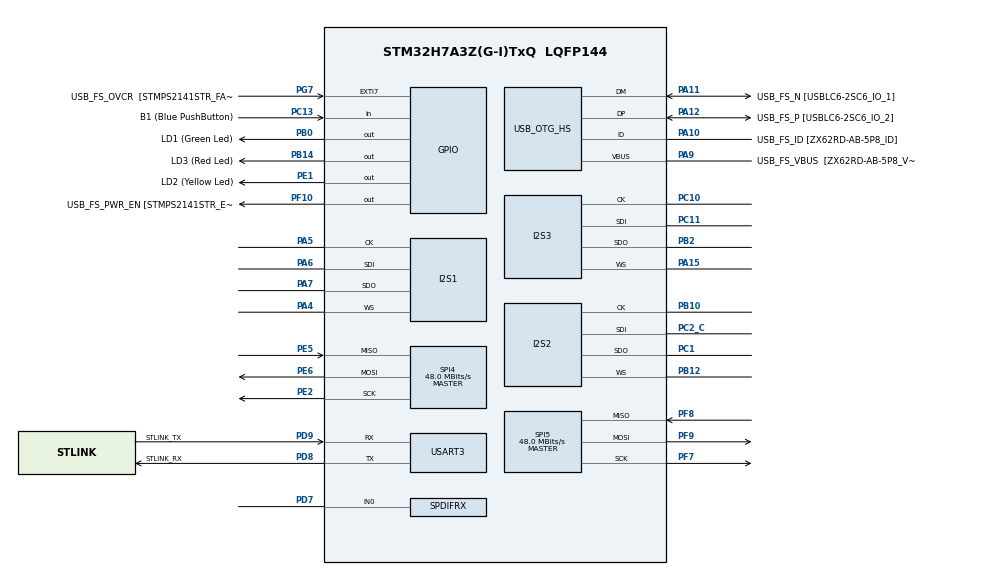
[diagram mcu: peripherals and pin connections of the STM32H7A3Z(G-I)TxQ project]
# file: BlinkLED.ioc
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I2S1.AudioFreq=I2S_AUDIOFREQ_48K
I2S1.ErrorAudioFreq=-0.79 %
I2S1.Instance=SPI$Index
I2S1.RealAudioFreq=47.619 KHz
I2S2.ErrorAudioFreq=0.0 %
I2S2.Instance=SPI$Index
I2S2.RealAudioFreq=8.0 KHz
I2S3.ErrorAudioFreq=0.0 %
I2S3.Instance=SPI$Index
I2S3.RealAudioFreq=8.0 KHz
Mcu.Family=STM32H7
Mcu.Name=STM32H7A3Z(G-I)TxQ
Mcu.Package=LQFP144
NVIC.PriorityGroup=NVIC_PRIORITYGROUP_4
PA10.GPIO_Label=USB_FS_ID [ZX62RD-AB-5P8_ID]
PA10.Mode=OTG/Dual-Role-Device-FS
PA10.Signal=USB_OTG_HS_ID
PA11.GPIO_Label=USB_FS_N [USBLC6-2SC6_IO_1]
PA11.Mode=OTG/Dual-Role-Device-FS
PA11.Signal=USB_OTG_HS_DM
PA12.GPIO_Label=USB_FS_P [USBLC6-2SC6_IO_2]
PA12.Mode=OTG/Dual-Role-Device-FS
PA12.Signal=USB_OTG_HS_DP
PA15.Mode=Full_Duplex_Master
PA15.Signal=I2S3_WS
PA4.Mode=Full_Duplex_Master
PA4.Signal=I2S1_WS
PA5.Mode=Full_Duplex_Master
PA5.Signal=I2S1_CK
PA6.Mode=Full_Duplex_Master
PA6.Signal=I2S1_SDI
PA7.Mode=Full_Duplex_Master
PA7.Signal=I2S1_SDO
PA9.GPIO_Label=USB_FS_VBUS  [ZX62RD-AB-5P8_VBUS]
PA9.Mode=Activate_VBUS_FS
PA9.Signal=USB_OTG_HS_VBUS
PB0.GPIO_Label=LD1 (Green Led)
PB0.Signal=GPIO_Output
PB10.Mode=Full_Duplex_Master
PB10.Signal=I2S2_CK
PB12.Mode=Full_Duplex_Master
PB12.Signal=I2S2_WS
PB14.GPIO_Label=LD3 (Red Led)
PB14.Signal=GPIO_Output
PB2.Mode=Full_Duplex_Master
PB2.Signal=I2S3_SDO
PC1.Mode=Full_Duplex_Master
PC1.Signal=I2S2_SDO
PC10.Mode=Full_Duplex_Master
PC10.Signal=I2S3_CK
PC11.Mode=Full_Duplex_Master
PC11.Signal=I2S3_SDI
PC13.GPIO_Label=B1 (Blue PushButton)
PC13.Signal=GPIO_Input
PC14-OSC32_IN.GPIO_Label=OSC32_IN
PC14-OSC32_IN.Mode=LSE-External-Oscillator
PC14-OSC32_IN.Signal=RCC_OSC32_IN
PC15-OSC32_OUT.GPIO_Label=OSC32_OUT
PC15-OSC32_OUT.Mode=LSE-External-Oscillator
PC15-OSC32_OUT.Signal=RCC_OSC32_OUT
PC2_C.Mode=Full_Duplex_Master
PC2_C.Signal=I2S2_SDI
PD7.Mode=IN0
PD7.Signal=SPDIFRX_IN0
PD8.GPIO_Label=STLINK_RX
PD8.Mode=Asynchronous
PD8.Signal=USART3_TX
PD9.GPIO_Label=STLINK_TX
PD9.Mode=Asynchronous
PD9.Signal=USART3_RX
PE1.GPIO_Label=LD2 (Yellow Led)
PE1.Signal=GPIO_Output
PE2.Mode=Full_Duplex_Master
PE2.Signal=SPI4_SCK
PE5.Mode=Full_Duplex_Master
PE5.Signal=SPI4_MISO
PE6.Mode=Full_Duplex_Master
PE6.Signal=SPI4_MOSI
PF10.GPIO_Label=USB_FS_PWR_EN [STMPS2141STR_EN]
PF10.Signal=GPIO_Output
PF7.Mode=Full_Duplex_Master
PF7.Signal=SPI5_SCK
PF8.Mode=Full_Duplex_Master
PF8.Signal=SPI5_MISO
PF9.Mode=Full_Duplex_Master
PF9.Signal=SPI5_MOSI
PG7.GPIO_Label=USB_FS_OVCR  [STMPS2141STR_FAULT]
PG7.Signal=GPXTI7
PH0-OSC_IN.GPIO_Label=PH0-MCU
PH0-OSC_IN.Mode=HSE-External-Clock-Source
PH0-OSC_IN.Signal=RCC_OSC_IN
PH1-OSC_OUT.GPIO_Label=PH1-MCU
PH1-OSC_OUT.Signal=RCC_OSC_OUT
ProjectManager.HeapSize=0x200
ProjectManager.StackSize=0x400
ProjectManager.TargetToolchain=MDK-ARM V5.32
RCC.ADCFreq_Value=32000000
RCC.APB1Freq_Value=96000000
RCC.APB2Freq_Value=96000000
RCC.APB3Freq_Value=96000000
RCC.APB4Freq_Value=96000000
RCC.CortexFreq_Value=96000000
RCC.DIVM1=1
RCC.DIVM2=1
RCC.DIVM3=1
RCC.DIVN1=24
RCC.DIVN2=16
RCC.DIVN3=24
RCC.DIVP2=4
RCC.DIVQ1=4
RCC.HCLKFreq_Value=96000000
RCC.HSE_VALUE=8000000
RCC.PLL3FRACN=0
RCC.PLLFRACN=0
RCC.PLLSourceVirtual=RCC_PLLSOURCE_HSE
RCC.PWR_Regulator_Voltage_Scale=PWR_REGULATOR_VOLTAGE_SCALE0
RCC.SPI123CLockSelection=RCC_SPI123CLKSOURCE_PLL3
RCC.SYSCLKFreq_VALUE=96000000
RCC.SYSCLKSource=RCC_SYSCLKSOURCE_PLLCLK
RCC.SupplySource=PWR_DIRECT_SMPS_SUPPLY
RCC.USBCLockSelection=RCC_USBCLKSOURCE_HSI48
RCC.USBFreq_Value=48000000
SPI4.CalculateBaudRate=48.0 MBits/s
SPI4.Direction=SPI_DIRECTION_2LINES
SPI4.Mode=SPI_MODE_MASTER
SPI4.VirtualType=VM_MASTER
SPI5.CalculateBaudRate=48.0 MBits/s
SPI5.Direction=SPI_DIRECTION_2LINES
SPI5.Mode=SPI_MODE_MASTER
SPI5.VirtualType=VM_MASTER
USART3.VirtualMode-Asynchronous=VM_ASYNC
VP_MEMORYMAP_VS_MEMORYMAP.Mode=CurAppReg
board=NUCLEO-H7A3ZI-Q

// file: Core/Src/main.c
/* USER CODE BEGIN Header */
/**
  ******************************************************************************
  * @file           : main.c
  * @brief          : Main program body
  ******************************************************************************
  * @attention
  *
  * Copyright (c) 2024 STMicroelectronics.
  * All rights reserved.
  *
  * This software is licensed under terms that can be found in the LICENSE file
  * in the root directory of this software component.
  * If no LICENSE file comes with this software, it is provided AS-IS.
  *
  ******************************************************************************
  */
/* USER CODE END Header */
#include "main.h"
#include "i2s.h"
#include "memorymap.h"
#include "spdifrx.h"
#include "spi.h"
#include "usart.h"
#include "usb_otg.h"
#include "gpio.h"

void SystemClock_Config(void);
void PeriphCommonClock_Config(void);

int main(void)
{

  /* MCU Configuration--------------------------------------------------------*/

  /* Reset of all peripherals, Initializes the Flash interface and the Systick. */
  HAL_Init();

  /* Configure the system clock */
  SystemClock_Config();

  /* Configure the peripherals common clocks */
  PeriphCommonClock_Config();

  /* Initialize all configured peripherals */
  MX_GPIO_Init();
  MX_I2S1_Init();
  MX_I2S2_Init();
  MX_I2S3_Init();
  MX_SPDIFRX_Init();
  MX_SPI4_Init();
  MX_SPI5_Init();
  MX_USART3_UART_Init();
  MX_USB_OTG_HS_USB_Init();

  /* Infinite loop */
  /* USER CODE BEGIN WHILE */
  while (1)
  {
		//while((GPIOC->IDR & GPIO_PIN_13));
		//while(!(GPIOC->IDR & GPIO_PIN_13));

    /* USER CODE END WHILE */
		HAL_GPIO_TogglePin(GPIOB, GPIO_PIN_14);
		HAL_Delay(1);
  }
}

void SystemClock_Config(void)
{
  RCC_OscInitTypeDef RCC_OscInitStruct = {0};
  RCC_ClkInitTypeDef RCC_ClkInitStruct = {0};

  /*AXI clock gating */
  RCC->CKGAENR = 0xFFFFFFFF;

  /** Supply configuration update enable
  */
  HAL_PWREx_ConfigSupply(PWR_DIRECT_SMPS_SUPPLY);

  /** Configure the main internal regulator output voltage
  */
  __HAL_PWR_VOLTAGESCALING_CONFIG(PWR_REGULATOR_VOLTAGE_SCALE0);

  while(!__HAL_PWR_GET_FLAG(PWR_FLAG_VOSRDY)) {}

  /** Initializes the RCC Oscillators according to the specified parameters
  * in the RCC_OscInitTypeDef structure.
  */
  RCC_OscInitStruct.OscillatorType = RCC_OSCILLATORTYPE_HSI48|RCC_OSCILLATORTYPE_HSE;
  RCC_OscInitStruct.HSEState = RCC_HSE_BYPASS;
  RCC_OscInitStruct.HSI48State = RCC_HSI48_ON;
  RCC_OscInitStruct.PLL.PLLState = RCC_PLL_ON;
  RCC_OscInitStruct.PLL.PLLSource = RCC_PLLSOURCE_HSE;
  RCC_OscInitStruct.PLL.PLLM = 1;
  RCC_OscInitStruct.PLL.PLLN = 24;
  RCC_OscInitStruct.PLL.PLLP = 2;
  RCC_OscInitStruct.PLL.PLLQ = 4;
  RCC_OscInitStruct.PLL.PLLR = 2;
  RCC_OscInitStruct.PLL.PLLRGE = RCC_PLL1VCIRANGE_3;
  RCC_OscInitStruct.PLL.PLLVCOSEL = RCC_PLL1VCOWIDE;
  RCC_OscInitStruct.PLL.PLLFRACN = 0;
  if (HAL_RCC_OscConfig(&RCC_OscInitStruct) != HAL_OK)
  {
    Error_Handler();
  }

  /** Initializes the CPU, AHB and APB buses clocks
  */
  RCC_ClkInitStruct.ClockType = RCC_CLOCKTYPE_HCLK|RCC_CLOCKTYPE_SYSCLK
                              |RCC_CLOCKTYPE_PCLK1|RCC_CLOCKTYPE_PCLK2
                              |RCC_CLOCKTYPE_D3PCLK1|RCC_CLOCKTYPE_D1PCLK1;
  RCC_ClkInitStruct.SYSCLKSource = RCC_SYSCLKSOURCE_PLLCLK;
  RCC_ClkInitStruct.SYSCLKDivider = RCC_SYSCLK_DIV1;
  RCC_ClkInitStruct.AHBCLKDivider = RCC_HCLK_DIV1;
  RCC_ClkInitStruct.APB3CLKDivider = RCC_APB3_DIV1;
  RCC_ClkInitStruct.APB1CLKDivider = RCC_APB1_DIV1;
  RCC_ClkInitStruct.APB2CLKDivider = RCC_APB2_DIV1;
  RCC_ClkInitStruct.APB4CLKDivider = RCC_APB4_DIV1;

  if (HAL_RCC_ClockConfig(&RCC_ClkInitStruct, FLASH_LATENCY_2) != HAL_OK)
  {
    Error_Handler();
  }
}

void PeriphCommonClock_Config(void)
{
  RCC_PeriphCLKInitTypeDef PeriphClkInitStruct = {0};

  /** Initializes the peripherals clock
  */
  PeriphClkInitStruct.PeriphClockSelection = RCC_PERIPHCLK_SPI3|RCC_PERIPHCLK_SPI2
                              |RCC_PERIPHCLK_SPI1;
  PeriphClkInitStruct.PLL3.PLL3M = 1;
  PeriphClkInitStruct.PLL3.PLL3N = 24;
  PeriphClkInitStruct.PLL3.PLL3P = 2;
  PeriphClkInitStruct.PLL3.PLL3Q = 2;
  PeriphClkInitStruct.PLL3.PLL3R = 2;
  PeriphClkInitStruct.PLL3.PLL3RGE = RCC_PLL3VCIRANGE_3;
  PeriphClkInitStruct.PLL3.PLL3VCOSEL = RCC_PLL3VCOWIDE;
  PeriphClkInitStruct.PLL3.PLL3FRACN = 0;
  PeriphClkInitStruct.Spi123ClockSelection = RCC_SPI123CLKSOURCE_PLL3;
  if (HAL_RCCEx_PeriphCLKConfig(&PeriphClkInitStruct) != HAL_OK)
  {
    Error_Handler();
  }
}

void Error_Handler(void)
{
  __disable_irq();
  while (1)
  {
  }
}
